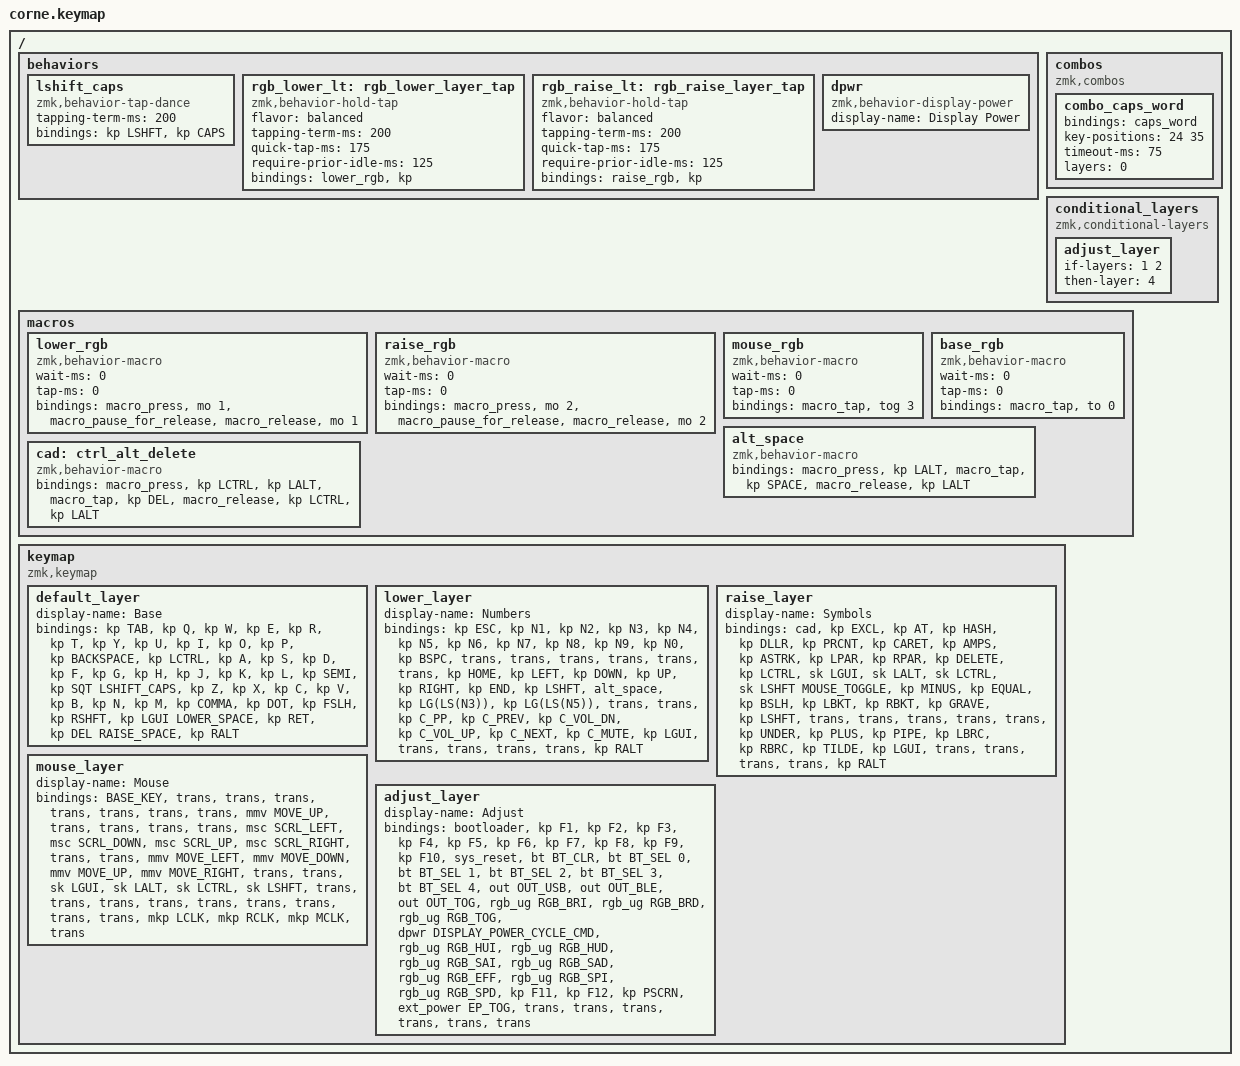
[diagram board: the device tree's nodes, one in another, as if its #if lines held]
/*
 * Copyright (c) 2020 The ZMK Contributors
 *
 * SPDX-License-Identifier: MIT
 */

#include <behaviors.dtsi>
#include <dt-bindings/zmk/bt.h>
#include <dt-bindings/zmk/keys.h>
#include <dt-bindings/zmk/mouse.h>
#include <dt-bindings/zmk/outputs.h>
#include <dt-bindings/zmk/rgb.h>
#include <dt-bindings/zmk/ext_power.h>
#include <dt-bindings/zmk/display_power.h>

#ifdef KEYMAP_DRAWER
#define LSHIFT_CAPS &kp LSHFT
#define LOWER_SPACE &lt 1 SPACE
#define RAISE_SPACE &lt 2 SPACE
#define MOUSE_TOGGLE &tog 3
#define BASE_KEY &to 0
#else
#define LSHIFT_CAPS &lshift_caps
#define LOWER_SPACE &rgb_lower_lt 0 SPACE
#define RAISE_SPACE &rgb_raise_lt 0 SPACE
#define MOUSE_TOGGLE &mouse_rgb
#define BASE_KEY &base_rgb
#endif

/ {
    behaviors {
        lshift_caps: lshift_caps {
            compatible = "zmk,behavior-tap-dance";
            #binding-cells = <0>;
            tapping-term-ms = <200>;
            bindings = <&kp LSHFT>, <&kp CAPS>;
        };

        rgb_lower_lt: rgb_lower_layer_tap {
            compatible = "zmk,behavior-hold-tap";
            #binding-cells = <2>;
            // Balanced + require-prior-idle-ms:
            // - Standalone space always taps regardless of hold duration. Good for slow/deliberate presses.
            // - During fast typing rolls (<125ms after last key), space instantly resolves as tap.
            //   Prevents space from being swallowed by quick subsequent key presses.
            // - Intentional layer activation still works: press space, then another key.
            flavor = "balanced";
            tapping-term-ms = <200>;
            quick-tap-ms = <175>;
            require-prior-idle-ms = <125>;
            bindings = <&lower_rgb>, <&kp>;
        };

        rgb_raise_lt: rgb_raise_layer_tap {
            compatible = "zmk,behavior-hold-tap";
            #binding-cells = <2>;
            // Balanced + require-prior-idle-ms:
            // - Standalone space always taps regardless of hold duration. Good for slow/deliberate presses.
            // - During fast typing rolls (<125ms after last key), space instantly resolves as tap.
            //   Prevents space from being swallowed by quick subsequent key presses.
            // - Intentional layer activation still works: press space, then another key.
            flavor = "balanced";
            tapping-term-ms = <200>;
            quick-tap-ms = <175>;
            require-prior-idle-ms = <125>;
            bindings = <&raise_rgb>, <&kp>;
        };

        dpwr: dpwr {
            compatible = "zmk,behavior-display-power";
            #binding-cells = <1>;
            display-name = "Display Power";
        };
    };

    combos {
        compatible = "zmk,combos";


        combo_caps_word {
            bindings = <&caps_word>;
            key-positions = <24 35>; // Left Shift + Right Shift
            timeout-ms = <75>;
            layers = <0>;
        };
    };

    conditional_layers {
        compatible = "zmk,conditional-layers";

        adjust_layer {
            if-layers = <1 2>;
            then-layer = <4>;
        };
    };

    macros {
        lower_rgb: lower_rgb {
            compatible = "zmk,behavior-macro";
            #binding-cells = <0>;
            wait-ms = <0>;
            tap-ms = <0>;
            bindings =
                <&macro_press &mo 1>,
                <&macro_pause_for_release>,
                <&macro_release &mo 1>;
        };

        raise_rgb: raise_rgb {
            compatible = "zmk,behavior-macro";
            #binding-cells = <0>;
            wait-ms = <0>;
            tap-ms = <0>;
            bindings =
                <&macro_press &mo 2>,
                <&macro_pause_for_release>,
                <&macro_release &mo 2>;
        };

        mouse_rgb: mouse_rgb {
            compatible = "zmk,behavior-macro";
            #binding-cells = <0>;
            wait-ms = <0>;
            tap-ms = <0>;
            bindings =
                <&macro_tap &tog 3>;
        };

        base_rgb: base_rgb {
            compatible = "zmk,behavior-macro";
            #binding-cells = <0>;
            wait-ms = <0>;
            tap-ms = <0>;
            bindings =
                <&macro_tap &to 0>;
        };

        alt_space: alt_space {
            compatible = "zmk,behavior-macro";
            #binding-cells = <0>;
            bindings =
                <&macro_press &kp LALT>,
                <&macro_tap &kp SPACE>,
                <&macro_release &kp LALT>;
        };

        cad: ctrl_alt_delete {
            compatible = "zmk,behavior-macro";
            #binding-cells = <0>;
            bindings =
                <&macro_press &kp LCTRL &kp LALT>,
                <&macro_tap &kp DEL>,
                <&macro_release &kp LCTRL &kp LALT>;
        };
    };

    keymap {
        compatible = "zmk,keymap";

        default_layer {
            display-name = "Base";

            // -----------------------------------------------------------------------------------------
            // |  TAB |  Q  |  W  |  E  |  R  |  T  |   |  Y  |  U   |  I  |  O  |  P  | BSPC |
            // | CTRL |  A  |  S  |  D  |  F  |  G  |   |  H  |  J   |  K  |  L  |  ;  |  '   |
            // | SHFT |  Z  |  X  |  C  |  V  |  B  |   |  N  |  M   |  ,  |  .  |  /  | SHFT |
            //                    | GUI | SPC/LWR | ENT |   | DEL | SPC/RSE | ALT |
            // Combo: both Shifts = Caps Word, double-tap left Shift = Caps Lock

            bindings = <
&kp TAB    &kp Q  &kp W  &kp E     &kp R          &kp T    &kp Y    &kp U          &kp I      &kp O    &kp P     &kp BACKSPACE
&kp LCTRL  &kp A  &kp S  &kp D     &kp F          &kp G    &kp H    &kp J          &kp K      &kp L    &kp SEMI  &kp SQT
LSHIFT_CAPS  &kp Z  &kp X  &kp C     &kp V          &kp B    &kp N    &kp M          &kp COMMA  &kp DOT  &kp FSLH  &kp RSHFT
                         &kp LGUI  LOWER_SPACE  &kp RET  &kp DEL  RAISE_SPACE  &kp RALT
            >;
        };

        lower_layer {
            display-name = "Numbers";

            // -----------------------------------------------------------------------------------------
            // |  ESC |  1  |  2  |  3  |  4  |  5  |   |  6  |  7  |  8  |  9  |  0  | BSPC |
            // |     |     |     |     |     |     |   | HOME| LFT | DWN |  UP | RGT | END  |
            // | SHFT| APP | SS3 | SS5 |     |     |   | PLAY| PRV | VDN | VUP | NXT | MUTE |
            //                    | GUI |     |     |   |     |      | ALT |

            bindings = <
&kp ESC     &kp N1           &kp N2        &kp N3           &kp N4        &kp N5             &kp N6      &kp N7      &kp N8       &kp N9      &kp N0     &kp BSPC
&trans     &trans          &trans       &trans          &trans       &trans          &kp HOME    &kp LEFT    &kp DOWN     &kp UP      &kp RIGHT  &kp END
&kp LSHFT  &alt_space      &kp LG(LS(N3)) &kp LG(LS(N5)) &trans       &trans          &kp C_PP    &kp C_PREV   &kp C_VOL_DN  &kp C_VOL_UP  &kp C_NEXT  &kp C_MUTE
                                           &kp LGUI         &trans        &trans             &trans      &trans      &kp RALT
            >;
        };

        raise_layer {
            display-name = "Symbols";

            // -----------------------------------------------------------------------------------------
            // | CAD  |  !  |  @  |  #  |  $  |  %  |   |  ^  |  &  |  *  |  (  |  )  | DEL  |
            // | CTRL | OSG | OSA | OSC | OSS |MOUS |   |  -  |  =  |  \  |  [  |  ]  |  `   |
            // | SHFT |     |     |     |     |     |   |  _  |  +  | "|" |  {  |  }  |  ~   |
            //                    | GUI |     |     |   |     |      | ALT |
            // OSG/OSA/OSC/OSS = one-shot GUI/ALT/CTRL/SHIFT
            // CAD = Ctrl + Alt + Delete, MOUS = Toggle Mouse Layer + RGB color

            bindings = <
&cad       &kp EXCL    &kp AT      &kp HASH    &kp DLLR    &kp PRCNT    &kp CARET  &kp AMPS   &kp ASTRK  &kp LPAR  &kp RPAR  &kp DELETE
&kp LCTRL  &sk LGUI    &sk LALT    &sk LCTRL   &sk LSHFT   MOUSE_TOGGLE  &kp MINUS  &kp EQUAL  &kp BSLH   &kp LBKT  &kp RBKT  &kp GRAVE
&kp LSHFT  &trans      &trans      &trans      &trans      &trans       &kp UNDER  &kp PLUS   &kp PIPE   &kp LBRC  &kp RBRC  &kp TILDE
                                  &kp LGUI    &trans      &trans       &trans     &trans     &kp RALT
            >;
        };

        mouse_layer {
            display-name = "Mouse";

            // -----------------------------------------------------------------------------------------
            // | BASE |     |     |     |     |     |   |     |     | MUP |     |     |      |
            // |      | OSG | OSA | OSC | OSS |     |   |     | MLFT| MDN | MUP | MRGT|      |
            // |      |     |     |     |     |     |   |     | SLFT| SDN | SUP | SRGT|      |
            //                    |     |     | LCLK|   | RCLK| MCLK |     |

            bindings = <
BASE_KEY  &trans          &trans          &trans        &trans        &trans    &trans    &trans          &mmv MOVE_UP    &trans        &trans           &trans
&trans   &msc SCRL_LEFT &msc SCRL_DOWN &msc SCRL_UP &msc SCRL_RIGHT &trans    &trans    &mmv MOVE_LEFT &mmv MOVE_DOWN  &mmv MOVE_UP  &mmv MOVE_RIGHT  &trans
&trans   &sk LGUI       &sk LALT       &sk LCTRL    &sk LSHFT    &trans    &trans    &trans         &trans          &trans        &trans           &trans
                                                  &trans    &trans    &mkp LCLK  &mkp RCLK     &mkp MCLK       &trans
            >;
        };

        adjust_layer {
            display-name = "Adjust";

            // -----------------------------------------------------------------------------------------
            // | BOOT | F1  | F2  | F3  | F4  | F5   |   | F6  | F7  | F8  | F9  | F10 | RESET|
            // | BTCLR| BT1 | BT2 | BT3 | BT4 | BT5  |   | USB | BLE | OUT | BRI+| BRI-| RGB  |
            // | DISP | HUE+| HUE-| SAT+| SAT-| RGBFX|   | SPD+| SPD-| F11 | F12 | PSCR| EPWR |
            //                    |     |     |     |   |     |      |     |
            // Adjust layer RGB color target: red-orange RGB_COLOR_HSB(15, 100, 30)

            bindings = <
&bootloader  &kp F1          &kp F2          &kp F3          &kp F4          &kp F5             &kp F6          &kp F7          &kp F8     &kp F9     &kp F10    &sys_reset
&bt BT_CLR   &bt BT_SEL 0    &bt BT_SEL 1    &bt BT_SEL 2    &bt BT_SEL 3    &bt BT_SEL 4       &out OUT_USB    &out OUT_BLE    &out OUT_TOG &rgb_ug RGB_BRI &rgb_ug RGB_BRD &rgb_ug RGB_TOG
&dpwr DISPLAY_POWER_CYCLE_CMD &rgb_ug RGB_HUI &rgb_ug RGB_HUD &rgb_ug RGB_SAI &rgb_ug RGB_SAD &rgb_ug RGB_EFF    &rgb_ug RGB_SPI &rgb_ug RGB_SPD &kp F11    &kp F12    &kp PSCRN  &ext_power EP_TOG
                                                       &trans          &trans          &trans             &trans          &trans          &trans
            >;
        };
    };
};
